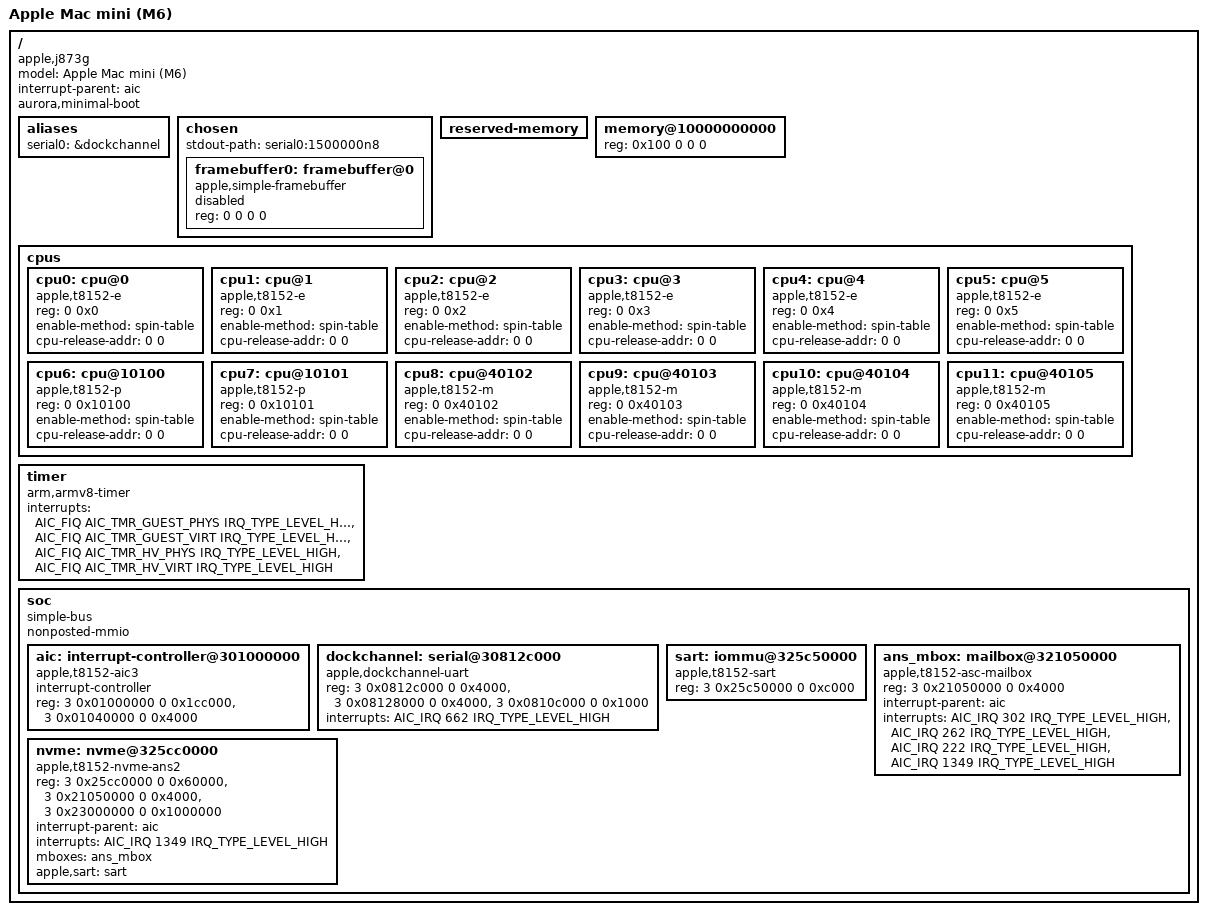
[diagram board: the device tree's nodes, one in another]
// SPDX-License-Identifier: GPL-2.0+ OR MIT
/*
 * Apple Mac mini (M6), J873g.
 *
 * Initial RAM boot resources measured on J873g/T8152.
 * The loader supplies usable memory, CPU release addresses and framebuffer
 * geometry. Peripheral power management is left with the boot firmware.
 */
/dts-v1/;

#include <dt-bindings/interrupt-controller/apple-aic.h>
#include <dt-bindings/interrupt-controller/irq.h>

/ {
	compatible = "apple,j873g", "apple,t8152", "apple,arm-platform";
	model = "Apple Mac mini (M6)";

	#address-cells = <2>;
	#size-cells = <2>;
	interrupt-parent = <&aic>;

	/* Request the m1n1 RAM-only handoff, without PCIe/DAPF setup. */
	aurora,minimal-boot;

	aliases {
		serial0 = &dockchannel;
	};

	chosen {
		#address-cells = <2>;
		#size-cells = <2>;
		ranges;

		stdout-path = "serial0:1500000n8";

		framebuffer0: framebuffer@0 {
			compatible = "apple,simple-framebuffer", "simple-framebuffer";
			reg = <0 0 0 0>; /* Filled by the loader. */
			status = "disabled";
		};
	};

	reserved-memory {
		#address-cells = <2>;
		#size-cells = <2>;
		ranges;
		/* Filled by the loader. */
	};

	memory@10000000000 {
		device_type = "memory";
		reg = <0x100 0 0 0>; /* Filled by the loader. */
	};

	cpus {
		#address-cells = <2>;
		#size-cells = <0>;

		cpu0: cpu@0 {
			compatible = "apple,t8152-e";
			device_type = "cpu";
			reg = <0 0x0>;
			enable-method = "spin-table";
			cpu-release-addr = <0 0>; /* Filled by the loader. */
		};

		cpu1: cpu@1 {
			compatible = "apple,t8152-e";
			device_type = "cpu";
			reg = <0 0x1>;
			enable-method = "spin-table";
			cpu-release-addr = <0 0>; /* Filled by the loader. */
		};

		cpu2: cpu@2 {
			compatible = "apple,t8152-e";
			device_type = "cpu";
			reg = <0 0x2>;
			enable-method = "spin-table";
			cpu-release-addr = <0 0>; /* Filled by the loader. */
		};

		cpu3: cpu@3 {
			compatible = "apple,t8152-e";
			device_type = "cpu";
			reg = <0 0x3>;
			enable-method = "spin-table";
			cpu-release-addr = <0 0>; /* Filled by the loader. */
		};

		cpu4: cpu@4 {
			compatible = "apple,t8152-e";
			device_type = "cpu";
			reg = <0 0x4>;
			enable-method = "spin-table";
			cpu-release-addr = <0 0>; /* Filled by the loader. */
		};

		cpu5: cpu@5 {
			compatible = "apple,t8152-e";
			device_type = "cpu";
			reg = <0 0x5>;
			enable-method = "spin-table";
			cpu-release-addr = <0 0>; /* Filled by the loader. */
		};

		cpu6: cpu@10100 {
			compatible = "apple,t8152-p";
			device_type = "cpu";
			reg = <0 0x10100>;
			enable-method = "spin-table";
			cpu-release-addr = <0 0>; /* Filled by the loader. */
		};

		cpu7: cpu@10101 {
			compatible = "apple,t8152-p";
			device_type = "cpu";
			reg = <0 0x10101>;
			enable-method = "spin-table";
			cpu-release-addr = <0 0>; /* Filled by the loader. */
		};

		cpu8: cpu@40102 {
			compatible = "apple,t8152-m";
			device_type = "cpu";
			reg = <0 0x40102>;
			enable-method = "spin-table";
			cpu-release-addr = <0 0>; /* Filled by the loader. */
		};

		cpu9: cpu@40103 {
			compatible = "apple,t8152-m";
			device_type = "cpu";
			reg = <0 0x40103>;
			enable-method = "spin-table";
			cpu-release-addr = <0 0>; /* Filled by the loader. */
		};

		cpu10: cpu@40104 {
			compatible = "apple,t8152-m";
			device_type = "cpu";
			reg = <0 0x40104>;
			enable-method = "spin-table";
			cpu-release-addr = <0 0>; /* Filled by the loader. */
		};

		cpu11: cpu@40105 {
			compatible = "apple,t8152-m";
			device_type = "cpu";
			reg = <0 0x40105>;
			enable-method = "spin-table";
			cpu-release-addr = <0 0>; /* Filled by the loader. */
		};
	};

	timer {
		compatible = "arm,armv8-timer";
		interrupts = <AIC_FIQ AIC_TMR_GUEST_PHYS IRQ_TYPE_LEVEL_HIGH>,
			     <AIC_FIQ AIC_TMR_GUEST_VIRT IRQ_TYPE_LEVEL_HIGH>,
			     <AIC_FIQ AIC_TMR_HV_PHYS IRQ_TYPE_LEVEL_HIGH>,
			     <AIC_FIQ AIC_TMR_HV_VIRT IRQ_TYPE_LEVEL_HIGH>;
		interrupt-names = "phys", "virt", "hyp-phys", "hyp-virt";
	};

	soc {
		compatible = "simple-bus";
		#address-cells = <2>;
		#size-cells = <2>;
		ranges;
		nonposted-mmio;

		aic: interrupt-controller@301000000 {
			compatible = "apple,t8152-aic3", "apple,t8122-aic3";
			interrupt-controller;
			#interrupt-cells = <3>;
			reg = <3 0x01000000 0 0x1cc000>,
			      <3 0x01040000 0 0x4000>;
			reg-names = "core", "event";
		};

		dockchannel: serial@30812c000 {
			compatible = "apple,dockchannel-uart";
			reg = <3 0x0812c000 0 0x4000>,
			      <3 0x08128000 0 0x4000>,
			      <3 0x0810c000 0 0x1000>;
			reg-names = "data", "config", "irq";
			interrupts = <AIC_IRQ 662 IRQ_TYPE_LEVEL_HIGH>;
		};
		sart: iommu@325c50000 {
			compatible = "apple,t8152-sart";
			reg = <3 0x25c50000 0 0xc000>;
		};

		ans_mbox: mailbox@321050000 {
			compatible = "apple,t8152-asc-mailbox", "apple,asc-mailbox-v4";
			reg = <3 0x21050000 0 0x4000>;
			interrupt-parent = <&aic>;
			interrupts = <AIC_IRQ 302 IRQ_TYPE_LEVEL_HIGH>,
				     <AIC_IRQ 262 IRQ_TYPE_LEVEL_HIGH>,
				     <AIC_IRQ 222 IRQ_TYPE_LEVEL_HIGH>,
				     <AIC_IRQ 1349 IRQ_TYPE_LEVEL_HIGH>;
			interrupt-names = "send-empty", "send-not-empty",
					  "recv-empty", "recv-not-empty";
			#mbox-cells = <0>;
		};

		nvme: nvme@325cc0000 {
			compatible = "apple,t8152-nvme-ans2", "apple,t8132-nvme-ans2";
			reg = <3 0x25cc0000 0 0x60000>,
			      <3 0x21050000 0 0x4000>,
			      <3 0x23000000 0 0x1000000>;
			reg-names = "nvme", "ans", "nvmmu";
			interrupt-parent = <&aic>;
			interrupts = <AIC_IRQ 1349 IRQ_TYPE_LEVEL_HIGH>;
			mboxes = <&ans_mbox>;
			apple,sart = <&sart>;
		};
	};
};
